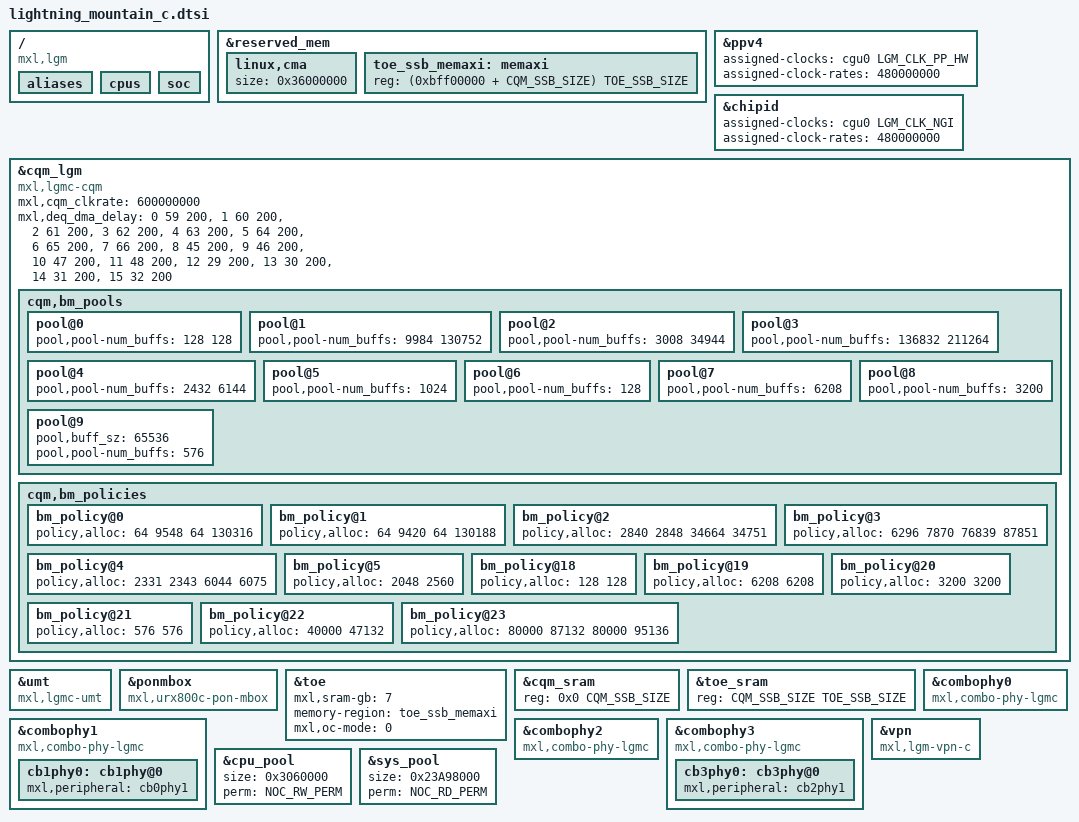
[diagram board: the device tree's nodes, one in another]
// SPDX-License-Identifier: GPL-2.0
/*
 * Copyright (C) 2023 - 2024 MaxLinear, Inc.
 */

#define LGMC_SOC
#include "lightning_mountain.dtsi"

/{
	compatible = "mxl,lgm", "intel,lgm", "mxl,lgmc";

	aliases {
		/delete-property/ usb0;
		/delete-property/ cpu2;
		/delete-property/ cpu3;
	};

	cpus {
		/delete-node/ cpu@8;
		/delete-node/ cpu@a;
	};

	soc {
		/delete-node/ usb@0;
		/delete-node/ sata@d1a00000;
		/delete-node/ sata@d1b00000;
		/delete-node/ sata@c1a00000;
		/delete-node/ sata@c1b00000;
	};
};

&reserved_mem {
		linux,cma {
		size = <0x36000000>;
		};
};

&ppv4 {
	assigned-clocks = <&cgu0 LGM_CLK_PP_HW>;
	assigned-clock-rates = <480000000>;
};

&chipid {
	assigned-clocks = <&cgu0 LGM_CLK_NGI>;
	assigned-clock-rates = <480000000>;
};

#define CQM_SSB_SIZE (0x8000)
#define TOE_SSB_SIZE (0x80000 - CQM_SSB_SIZE)

&cqm_lgm {
	compatible = "mxl,lgmc-cqm";
	mxl,cqm_clkrate = <600000000>;
	mxl,deq_dma_delay = <0 59 200>, /* DCP0  - DOCSIS FIFO 0 */
			    <1 60 200>, /* DCP1  - DOCSIS FIFO 1 */
			    <2 61 200>, /* DCP2  - DOCSIS FIFO 2 */
			    <3 62 200>, /* DCP3  - DOCSIS FIFO 3 */
			    <4 63 200>, /* DCP4  - DOCSIS FIFO 4 */
			    <5 64 200>, /* DCP5  - DOCSIS FIFO 5 */
			    <6 65 200>, /* DCP6  - DOCSIS FIFO 6 */
			    <7 66 200>, /* DCP7  - DOCSIS FIFO 7 */
			    <8 45 200>, /* DCP8  - FSQM Q4 */
			    <9 46 200>, /* DCP9  - FSQM Q5 */
			    <10 47 200>, /* DCP10 - FSQM Q6 */
			    <11 48 200>, /* DCP11 - FSQM Q7 */
			    <12 29 200>, /* DCP12 - FSQM Q0 */
			    <13 30 200>, /* DCP13 - FSQM Q1 */
			    <14 31 200>, /* DCP14 - FSQM Q2 */
			    <15 32 200>; /* DCP15 - FSQM Q3 */
	cqm,bm_pools {
		pool@0 {
			/* Default, PON Systems */
			pool,pool-num_buffs = <128 128>;
		};
		pool@1 {
			pool,pool-num_buffs = <9984 130752>;
		};
		pool@2 {
			pool,pool-num_buffs = <3008 34944>;
		};
		pool@3 {
			pool,pool-num_buffs = <136832 211264>;
		};
		pool@4 {
			pool,pool-num_buffs = <2432 6144>;
		};
		/* Voice Pool: type = CQM_NIOC_ISOLATED */
		pool@5 {
			pool,pool-num_buffs = <1024>;
		};
		/* CPU Pools: type = CQM_CPU_ISOLATED */
		pool@6 {
			pool,pool-num_buffs = <128>;
		};
		pool@7 {
			pool,pool-num_buffs = <6208>;
		};
		pool@8 {
			pool,pool-num_buffs = <3200>;
		};
		pool@9 {
			pool,buff_sz = <65536>;
			pool,pool-num_buffs = <576>;
		};
	};
	cqm,bm_policies{
		bm_policy@0 {
			policy,alloc = <64 9548 64 130316>; /* If PON is enabled */
		};
		bm_policy@1 {
			policy,alloc = <64 9420 64 130188>;
		};
		bm_policy@2 {
			policy,alloc = <2840 2848 34664 34751>;
		};
		bm_policy@3 {
			policy,alloc = <6296 7870 76839 87851>;
		};
		bm_policy@4 {
			policy,alloc = <2331 2343 6044 6075>;
		};
		/* TOE TX policy */
		bm_policy@5 {
			policy,alloc = <2048 2560>;
		};
		/* CPU Policies */
		bm_policy@18 {
			policy,alloc = <128 128>;
		};
		bm_policy@19 {
			policy,alloc = <6208 6208>;
		};
		bm_policy@20 {
			policy,alloc = <3200 3200>;
		};
		bm_policy@21 {
			policy,alloc = <576 576>;
		};
		bm_policy@22 {
			policy,alloc = <40000 47132>;
		};
		bm_policy@23 {
			policy,alloc = <80000 87132 80000 95136>;
		};
	};
};

&umt {
	compatible = "mxl,lgmc-umt";
};

&ponmbox {
	compatible = "mxl,urx800c-pon-mbox";
};

&reserved_mem {
	toe_ssb_memaxi: memaxi {
		reg = <(0xbff00000 + CQM_SSB_SIZE) TOE_SSB_SIZE>;
	};
};

&toe {
	mxl,sram-gb = <7>;
	memory-region = <&toe_ssb_memaxi>;
	mxl,oc-mode = <0>;
};

&cqm_sram {
	reg = <0x0 CQM_SSB_SIZE>;
};

&toe_sram {
	reg = <CQM_SSB_SIZE TOE_SSB_SIZE>;
};

&combophy0 {
	compatible = "mxl,combo-phy-lgmc", "simple-bus";
};

&combophy1 {
	compatible = "mxl,combo-phy-lgmc", "simple-bus";
	cb1phy0:cb1phy@0 {
		mxl,peripheral = <&cb0phy1>; /* This property must be deleted to configure to pcie mode, default mode is C10PHY mode*/
	};
};

&combophy2 {
	compatible = "mxl,combo-phy-lgmc", "simple-bus";
};

&combophy3 {
	compatible = "mxl,combo-phy-lgmc", "simple-bus";
	cb3phy0:cb3phy@0 {
		mxl,peripheral = <&cb2phy1>; /* This property must be deleted to configure to pcie mode, default mode is C10PHY mode*/

	};
};

&vpn {
	compatible = "mxl,lgm-vpn-c";
};

&cpu_pool {
	size = <0x3060000>;
	perm = <NOC_RW_PERM>;
};

&sys_pool {
	size = <0x23A98000>;
	perm = <NOC_RD_PERM>;
};
